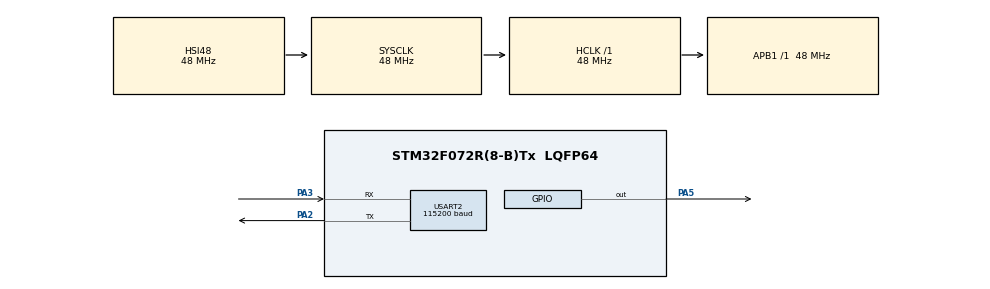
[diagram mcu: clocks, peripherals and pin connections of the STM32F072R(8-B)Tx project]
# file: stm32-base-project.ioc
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Mcu.Family=STM32F0
Mcu.Name=STM32F072R(8-B)Tx
Mcu.Package=LQFP64
NVIC.USART2_IRQn=true\:0\:0\:false\:false\:true\:true\:true\:true
PA2.Mode=Asynchronous
PA2.Signal=USART2_TX
PA3.Mode=Asynchronous
PA3.Signal=USART2_RX
PA5.Signal=GPIO_Output
ProjectManager.HeapSize=0x200
ProjectManager.StackSize=0x400
ProjectManager.TargetToolchain=STM32CubeIDE
RCC.AHBFreq_Value=48000000
RCC.APB1Freq_Value=48000000
RCC.APB1TimFreq_Value=48000000
RCC.HCLKFreq_Value=48000000
RCC.SYSCLKFreq_VALUE=48000000
RCC.SYSCLKSource=RCC_SYSCLKSOURCE_HSI48
USART2.BaudRate=115200
USART2.VirtualMode-Asynchronous=VM_ASYNC
board=custom

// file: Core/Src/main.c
/* USER CODE BEGIN Header */
/**
  ******************************************************************************
  * @file           : main.c
  * @brief          : Main program body
  ******************************************************************************
  * @attention
  *
  * Copyright (c) 2022 STMicroelectronics.
  * All rights reserved.
  *
  * This software is licensed under terms that can be found in the LICENSE file
  * in the root directory of this software component.
  * If no LICENSE file comes with this software, it is provided AS-IS.
  *
  ******************************************************************************
  */
/* USER CODE END Header */
#include "main.h"

/* USER CODE BEGIN Includes */

// FreeRTOS headers
#include "FreeRTOSConfig.h"
#include "FreeRTOS.h"
#include "task.h"
#include "timers.h"
#include "semphr.h"
#include "queue.h"
#include "event_groups.h"
#include "stream_buffer.h"

/* USER CODE END Includes */

UART_HandleTypeDef huart2;

/* USER CODE BEGIN PV */

static SemaphoreHandle_t usart2WriteMutex;
static SemaphoreHandle_t usart2ReadMutex;

/* USER CODE END PV */

void SystemClock_Config(void);
static void MX_GPIO_Init(void);
static void MX_USART2_UART_Init(void);
/* USER CODE BEGIN PFP */

/*
 * Redefinition of newlib functions to redirect stdout and stdin to USART2
 */
int _write(int fd, char *ptr, int len);
int _read (int fd, char *ptr, int len);

/* USER CODE END PFP */

int main(void)
{

  /* MCU Configuration--------------------------------------------------------*/

  /* Reset of all peripherals, Initializes the Flash interface and the Systick. */
  HAL_Init();

  /* Configure the system clock */
  SystemClock_Config();

  /* Initialize all configured peripherals */
  MX_GPIO_Init();
  MX_USART2_UART_Init();
  /* USER CODE BEGIN 2 */
  app();
  /* USER CODE END 2 */

  /* Infinite loop */
  while (1)
  {

  }
}

void SystemClock_Config(void)
{
  RCC_OscInitTypeDef RCC_OscInitStruct = {0};
  RCC_ClkInitTypeDef RCC_ClkInitStruct = {0};
  RCC_PeriphCLKInitTypeDef PeriphClkInit = {0};

  /** Initializes the RCC Oscillators according to the specified parameters
  * in the RCC_OscInitTypeDef structure.
  */
  RCC_OscInitStruct.OscillatorType = RCC_OSCILLATORTYPE_HSI48;
  RCC_OscInitStruct.HSI48State = RCC_HSI48_ON;
  RCC_OscInitStruct.PLL.PLLState = RCC_PLL_NONE;
  if (HAL_RCC_OscConfig(&RCC_OscInitStruct) != HAL_OK)
  {
    Error_Handler();
  }

  /** Initializes the CPU, AHB and APB buses clocks
  */
  RCC_ClkInitStruct.ClockType = RCC_CLOCKTYPE_HCLK|RCC_CLOCKTYPE_SYSCLK
                              |RCC_CLOCKTYPE_PCLK1;
  RCC_ClkInitStruct.SYSCLKSource = RCC_SYSCLKSOURCE_HSI48;
  RCC_ClkInitStruct.AHBCLKDivider = RCC_SYSCLK_DIV1;
  RCC_ClkInitStruct.APB1CLKDivider = RCC_HCLK_DIV1;

  if (HAL_RCC_ClockConfig(&RCC_ClkInitStruct, FLASH_LATENCY_1) != HAL_OK)
  {
    Error_Handler();
  }
  PeriphClkInit.PeriphClockSelection = RCC_PERIPHCLK_USART2;
  PeriphClkInit.Usart2ClockSelection = RCC_USART2CLKSOURCE_PCLK1;
  if (HAL_RCCEx_PeriphCLKConfig(&PeriphClkInit) != HAL_OK)
  {
    Error_Handler();
  }
}

static void MX_USART2_UART_Init(void)
{

  huart2.Instance = USART2;
  huart2.Init.BaudRate = 115200;
  huart2.Init.WordLength = UART_WORDLENGTH_8B;
  huart2.Init.StopBits = UART_STOPBITS_1;
  huart2.Init.Parity = UART_PARITY_NONE;
  huart2.Init.Mode = UART_MODE_TX_RX;
  huart2.Init.HwFlowCtl = UART_HWCONTROL_NONE;
  huart2.Init.OverSampling = UART_OVERSAMPLING_16;
  huart2.Init.OneBitSampling = UART_ONE_BIT_SAMPLE_DISABLE;
  huart2.AdvancedInit.AdvFeatureInit = UART_ADVFEATURE_NO_INIT;
  if (HAL_UART_Init(&huart2) != HAL_OK)
  {
    Error_Handler();
  }
  /* USER CODE BEGIN USART2_Init 2 */

  usart2WriteMutex = xSemaphoreCreateMutex();
  usart2ReadMutex = xSemaphoreCreateMutex();

  /* USER CODE END USART2_Init 2 */

}

static void MX_GPIO_Init(void)
{
  GPIO_InitTypeDef GPIO_InitStruct = {0};

  /* GPIO Ports Clock Enable */
  __HAL_RCC_GPIOA_CLK_ENABLE();

  /*Configure GPIO pin Output Level */
  HAL_GPIO_WritePin(GPIOA, GPIO_PIN_5, GPIO_PIN_RESET);

  /*Configure GPIO pin : PA5 */
  GPIO_InitStruct.Pin = GPIO_PIN_5;
  GPIO_InitStruct.Mode = GPIO_MODE_OUTPUT_PP;
  GPIO_InitStruct.Pull = GPIO_NOPULL;
  GPIO_InitStruct.Speed = GPIO_SPEED_FREQ_LOW;
  HAL_GPIO_Init(GPIOA, &GPIO_InitStruct);

}

/* USER CODE BEGIN 4 */

int _write(int fd, char *ptr, int len)
{
	xSemaphoreTake(usart2WriteMutex, portMAX_DELAY);

	while(huart2.gState != HAL_UART_STATE_READY) {
		vTaskDelay(1);
	}

	HAL_UART_Transmit_IT(&huart2, (uint8_t *) ptr, len);

	xSemaphoreGive(usart2WriteMutex);

	return len;
}

int _read (int fd, char *ptr, int len)
{

	//quick fix for length problem (VERY INEFFICIENT !!!)
	len = (len < 1) ? len : 1;

	xSemaphoreTake(usart2ReadMutex, portMAX_DELAY);

	while(huart2.RxState != HAL_UART_STATE_READY) {
		vTaskDelay(1);
	}

	HAL_UART_Receive_IT(&huart2, (uint8_t *) ptr, len);

	while(huart2.RxState != HAL_UART_STATE_READY) {
		vTaskDelay(1);
	}

	xSemaphoreGive(usart2ReadMutex);

	return len;
}

/* USER CODE END 4 */

void Error_Handler(void)
{
  __disable_irq();
  while (1)
  {
  }
}
